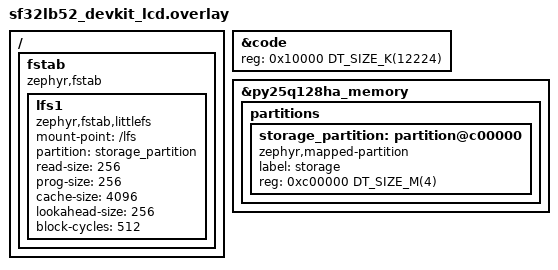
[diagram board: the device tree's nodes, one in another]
/*
 * SPDX-FileCopyrightText: Copyright The Zephyr Project Contributors
 * SPDX-License-Identifier: Apache-2.0
 */

&code {
	reg = <0x10000 DT_SIZE_K(12224)>;
};

/ {
	fstab {
		compatible = "zephyr,fstab";

		lfs1: lfs1 {
			compatible = "zephyr,fstab,littlefs";
			mount-point = "/lfs";
			partition = <&storage_partition>;
			read-size = <256>;
			prog-size = <256>;
			cache-size = <4096>;
			lookahead-size = <256>;
			block-cycles = <512>;
		};
	};
};

&py25q128ha_memory {
	partitions {
		storage_partition: partition@c00000 {
			compatible = "zephyr,mapped-partition";
			label = "storage";
			reg = <0xc00000 DT_SIZE_M(4)>;
		};
	};
};
